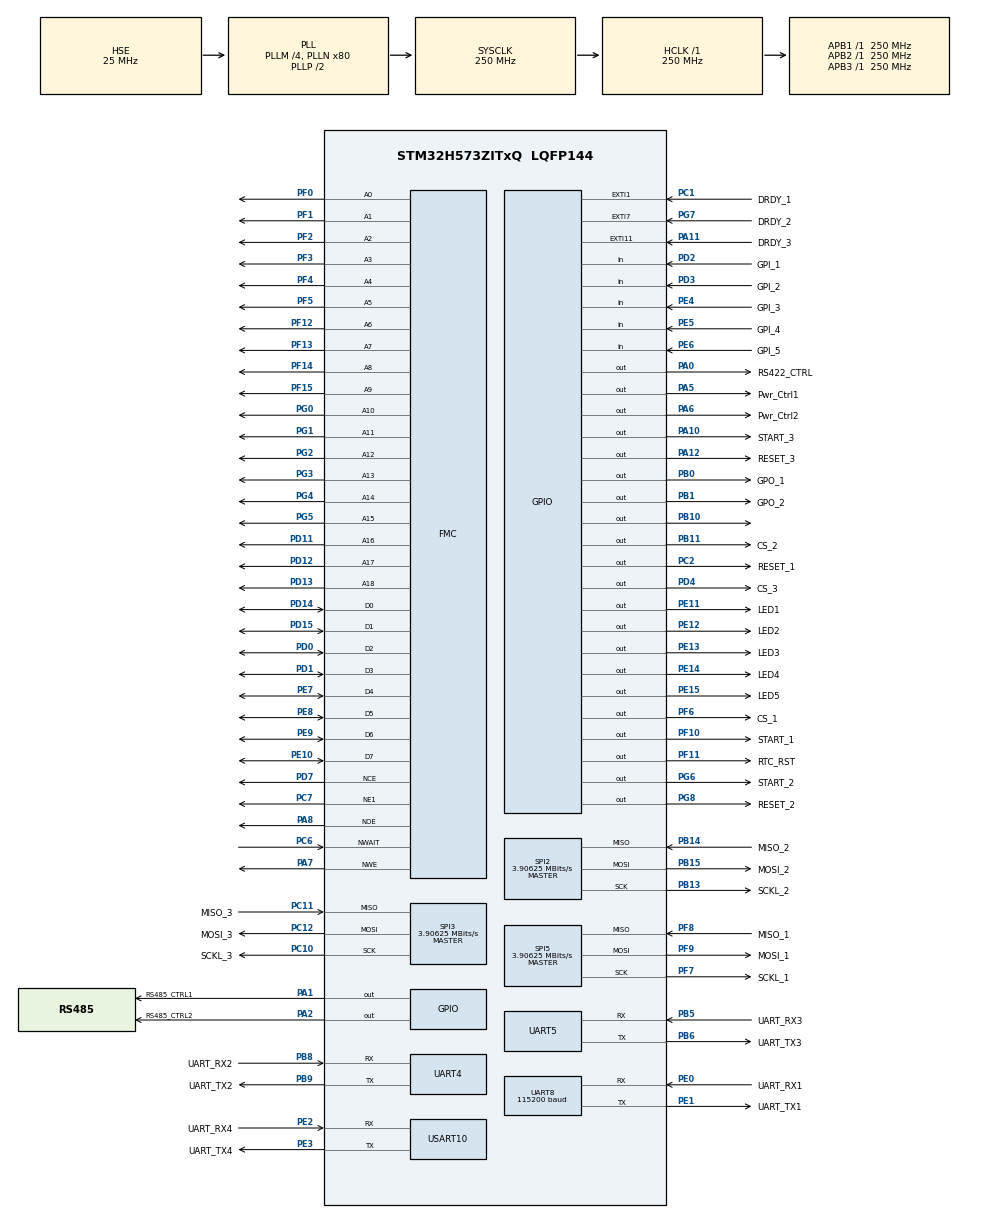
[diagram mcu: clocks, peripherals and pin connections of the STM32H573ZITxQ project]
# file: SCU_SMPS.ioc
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BOOTPATH.BootPathName=LEGACY
BOOTPATH.UserSelectedBootPath=LEGACY
CORTEX_M33_NS.userName=CORTEX_M33
FMC.AttributeSpaceHiZSetupTime1=9
FMC.AttributeSpaceHoldSetupTime1=10
FMC.AttributeSpaceSetupTime1=19
FMC.AttributeSpaceWaitSetupTime1=19
FMC.CommonSpaceHiZSetupTime1=3
FMC.CommonSpaceHoldSetupTime1=6
FMC.CommonSpaceSetupTime1=19
FMC.CommonSpaceWaitSetupTime1=19
FMC.DataHoldTime1=3
FMC.ECCPageSize1=FMC_NAND_ECC_PAGE_SIZE_8192BYTE
FMC.EccComputation1=FMC_NAND_ECC_ENABLE
FMC.NandBlockNbr1=4096
FMC.NandBlockSize1=128
FMC.NandExtraCommandEnable1=DISABLE
FMC.NandPageSize1=8192
FMC.NandPlaneNbr1=2
FMC.NandPlaneSize1=2048
FMC.NandSpareAreaSize1=448
FMC.TARSetupTime1=15
FMC.TCLRSetupTime1=15
FMC.WriteOperation1=FMC_WRITE_OPERATION_ENABLE
Mcu.Family=STM32H5
Mcu.Name=STM32H573ZITxQ
Mcu.Package=LQFP144
NVIC.EXTI11_IRQn=true\:0\:0\:false\:false\:true\:true\:true\:true
NVIC.EXTI1_IRQn=true\:0\:0\:false\:false\:true\:true\:true\:true
NVIC.EXTI7_IRQn=true\:0\:0\:false\:false\:true\:true\:true\:true
NVIC.PriorityGroup=NVIC_PRIORITYGROUP_4
NVIC.UART4_IRQn=true\:0\:0\:false\:false\:true\:true\:true\:true
NVIC.UART5_IRQn=true\:0\:0\:false\:false\:true\:true\:true\:true
NVIC.UART8_IRQn=true\:0\:0\:false\:false\:true\:true\:true\:true
PA0.GPIO_Label=RS422_CTRL
PA0.PinAttribute=Free
PA0.Signal=GPIO_Output
PA1.GPIO_Label=RS485_CTRL1
PA1.PinAttribute=Free
PA1.Signal=GPIO_Output
PA10.GPIO_Label=START_3
PA10.GPIO_Speed=GPIO_SPEED_FREQ_VERY_HIGH
PA10.Signal=GPIO_Output
PA11.GPIO_Label=DRDY_3
PA11.GPIO_ModeDefaultEXTI=GPIO_MODE_IT_FALLING
PA11.Signal=GPXTI11
PA12.GPIO_Label=RESET_3
PA12.GPIO_Speed=GPIO_SPEED_FREQ_VERY_HIGH
PA12.Signal=GPIO_Output
PA2.GPIO_Label=RS485_CTRL2
PA2.PinAttribute=Free
PA2.Signal=GPIO_Output
PA5.GPIO_Label=Pwr_Ctrl1
PA5.PinAttribute=Free
PA5.Signal=GPIO_Output
PA6.GPIO_Label=Pwr_Ctrl2
PA6.PinAttribute=Free
PA6.Signal=GPIO_Output
PA7.PinAttribute=Free
PA7.Signal=FMC_NWE
PA8.Signal=FMC_NOE
PB0.GPIO_Label=GPO_1
PB0.PinAttribute=Free
PB0.Signal=GPIO_Output
PB1.GPIO_Label=GPO_2
PB1.PinAttribute=Free
PB1.Signal=GPIO_Output
PB10.GPIO_Speed=GPIO_SPEED_FREQ_VERY_HIGH
PB10.PinAttribute=Free
PB10.PinState=GPIO_PIN_SET
PB10.Signal=GPIO_Output
PB11.GPIO_Label=CS_2
PB11.GPIO_Speed=GPIO_SPEED_FREQ_VERY_HIGH
PB11.PinAttribute=Free
PB11.Signal=GPIO_Output
PB13.GPIO_Label=SCKL_2
PB13.Mode=Full_Duplex_Master
PB13.Signal=SPI2_SCK
PB14.GPIO_Label=MISO_2
PB14.Mode=Full_Duplex_Master
PB14.PinAttribute=Free
PB14.Signal=SPI2_MISO
PB15.GPIO_Label=MOSI_2
PB15.Mode=Full_Duplex_Master
PB15.PinAttribute=Free
PB15.Signal=SPI2_MOSI
PB5.GPIO_Label=UART_RX3
PB5.Mode=Asynchronous
PB5.PinAttribute=Free
PB5.Signal=UART5_RX
PB6.GPIO_Label=UART_TX3
PB6.Mode=Asynchronous
PB6.PinAttribute=Free
PB6.Signal=UART5_TX
PB8.GPIO_Label=UART_RX2
PB8.Mode=Asynchronous
PB8.PinAttribute=Free
PB8.Signal=UART4_RX
PB9.GPIO_Label=UART_TX2
PB9.Mode=Asynchronous
PB9.PinAttribute=Free
PB9.Signal=UART4_TX
PC1.GPIO_Label=DRDY_1
PC1.GPIO_ModeDefaultEXTI=GPIO_MODE_IT_FALLING
PC1.PinAttribute=Free
PC1.Signal=GPXTI1
PC10.GPIO_Label=SCKL_3
PC10.Mode=Full_Duplex_Master
PC10.Signal=SPI3_SCK
PC11.GPIO_Label=MISO_3
PC11.Mode=Full_Duplex_Master
PC11.Signal=SPI3_MISO
PC12.GPIO_Label=MOSI_3
PC12.Mode=Full_Duplex_Master
PC12.Signal=SPI3_MOSI
PC14-OSC32_IN(OSC32_IN).Mode=LSE-External-Oscillator
PC14-OSC32_IN(OSC32_IN).Signal=RCC_OSC32_IN
PC15-OSC32_OUT(OSC32_OUT).Mode=LSE-External-Oscillator
PC15-OSC32_OUT(OSC32_OUT).Signal=RCC_OSC32_OUT
PC2.GPIO_Label=RESET_1
PC2.GPIO_Speed=GPIO_SPEED_FREQ_VERY_HIGH
PC2.PinAttribute=Free
PC2.Signal=GPIO_Output
PC6.Signal=FMC_NWAIT
PC7.Mode=NorPsramChipSelect1_1
PC7.Signal=FMC_NE1
PD0.PinAttribute=Free
PD0.Signal=FMC_D2_DA2
PD1.PinAttribute=Free
PD1.Signal=FMC_D3_DA3
PD11.PinAttribute=Free
PD11.Signal=FMC_A16_CLE
PD12.PinAttribute=Free
PD12.Signal=FMC_A17_ALE
PD13.PinAttribute=Free
PD13.Signal=FMC_A18
PD14.PinAttribute=Free
PD14.Signal=FMC_D0_DA0
PD15.PinAttribute=Free
PD15.Signal=FMC_D1_DA1
PD2.GPIO_Label=GPI_1
PD2.PinAttribute=Free
PD2.Signal=GPIO_Input
PD3.GPIO_Label=GPI_2
PD3.PinAttribute=Free
PD3.Signal=GPIO_Input
PD4.GPIO_Label=CS_3
PD4.GPIO_Speed=GPIO_SPEED_FREQ_VERY_HIGH
PD4.PinAttribute=Free
PD4.Signal=GPIO_Output
PD7.Mode=NandChipSelect3_1
PD7.PinAttribute=Free
PD7.Signal=FMC_NCE
PE0.GPIO_Label=UART_RX1
PE0.Mode=Asynchronous
PE0.PinAttribute=Free
PE0.Signal=UART8_RX
PE1.GPIO_Label=UART_TX1
PE1.Mode=Asynchronous
PE1.PinAttribute=Free
PE1.Signal=UART8_TX
PE10.PinAttribute=Free
PE10.Signal=FMC_D7_DA7
PE11.GPIO_Label=LED1
PE11.PinAttribute=Free
PE11.Signal=GPIO_Output
PE12.GPIO_Label=LED2
PE12.PinAttribute=Free
PE12.Signal=GPIO_Output
PE13.GPIO_Label=LED3
PE13.PinAttribute=Free
PE13.Signal=GPIO_Output
PE14.GPIO_Label=LED4
PE14.PinAttribute=Free
PE14.Signal=GPIO_Output
PE15.GPIO_Label=LED5
PE15.PinAttribute=Free
PE15.Signal=GPIO_Output
PE2.GPIO_Label=UART_RX4
PE2.Mode=Asynchronous
PE2.PinAttribute=Free
PE2.Signal=USART10_RX
PE3.GPIO_Label=UART_TX4
PE3.Mode=Asynchronous
PE3.PinAttribute=Free
PE3.Signal=USART10_TX
PE4.GPIO_Label=GPI_3
PE4.PinAttribute=Free
PE4.Signal=GPIO_Input
PE5.GPIO_Label=GPI_4
PE5.Signal=GPIO_Input
PE6.GPIO_Label=GPI_5
PE6.Signal=GPIO_Input
PE7.Signal=FMC_D4_DA4
PE8.PinAttribute=Free
PE8.Signal=FMC_D5_DA5
PE9.PinAttribute=Free
PE9.Signal=FMC_D6_DA6
PF0.Signal=FMC_A0
PF1.Signal=FMC_A1
PF10.GPIO_Label=START_1 
PF10.GPIO_Speed=GPIO_SPEED_FREQ_VERY_HIGH
PF10.PinAttribute=Free
PF10.Signal=GPIO_Output
PF11.GPIO_Label=RTC_RST
PF11.PinAttribute=Free
PF11.Signal=GPIO_Output
PF12.PinAttribute=Free
PF12.Signal=FMC_A6
PF13.PinAttribute=Free
PF13.Signal=FMC_A7
PF14.PinAttribute=Free
PF14.Signal=FMC_A8
PF15.PinAttribute=Free
PF15.Signal=FMC_A9
PF2.Signal=FMC_A2
PF3.Signal=FMC_A3
PF4.Signal=FMC_A4
PF5.Signal=FMC_A5
PF6.GPIO_Label=CS_1
PF6.GPIO_Speed=GPIO_SPEED_FREQ_VERY_HIGH
PF6.Signal=GPIO_Output
PF7.GPIO_Label=SCKL_1
PF7.Mode=Full_Duplex_Master
PF7.Signal=SPI5_SCK
PF8.GPIO_Label=MISO_1
PF8.Mode=Full_Duplex_Master
PF8.PinAttribute=Free
PF8.Signal=SPI5_MISO
PF9.GPIO_Label=MOSI_1
PF9.Mode=Full_Duplex_Master
PF9.PinAttribute=Free
PF9.Signal=SPI5_MOSI
PG0.Signal=FMC_A10
PG1.Signal=FMC_A11
PG2.PinAttribute=Free
PG2.Signal=FMC_A12
PG3.Signal=FMC_A13
PG4.Signal=FMC_A14_BA0
PG5.Signal=FMC_A15_BA1
PG6.GPIO_Label=START_2 
PG6.GPIO_Speed=GPIO_SPEED_FREQ_VERY_HIGH
PG6.Signal=GPIO_Output
PG7.GPIO_Label=DRDY_2
PG7.GPIO_ModeDefaultEXTI=GPIO_MODE_IT_FALLING
PG7.Signal=GPXTI7
PG8.GPIO_Label=RESET_2
PG8.GPIO_Speed=GPIO_SPEED_FREQ_VERY_HIGH
PG8.Signal=GPIO_Output
PH0-OSC_IN(PH0).Mode=HSE-External-Oscillator
PH0-OSC_IN(PH0).Signal=RCC_OSC_IN
PH1-OSC_OUT(PH1).Mode=HSE-External-Oscillator
PH1-OSC_OUT(PH1).Signal=RCC_OSC_OUT
ProjectManager.HeapSize=0x200
ProjectManager.StackSize=0x400
ProjectManager.TargetToolchain=STM32CubeIDE
RCC.ADCFreq_Value=250000000
RCC.AHBFreq_Value=250000000
RCC.APB1Freq_Value=250000000
RCC.APB1TimFreq_Value=250000000
RCC.APB2Freq_Value=250000000
RCC.APB2TimFreq_Value=250000000
RCC.APB3Freq_Value=250000000
RCC.CSI_VALUE=4000000
RCC.CortexFreq_Value=250000000
RCC.EPOD_VALUE=25000000
RCC.HCLKFreq_Value=250000000
RCC.HSE_VALUE=25000000
RCC.HSI48_VALUE=48000000
RCC.HSI_VALUE=64000000
RCC.LSIRC_VALUE=32000
RCC.PLLM=4
RCC.PLLN=80
RCC.PLLSourceVirtual=RCC_PLL1_SOURCE_HSE
RCC.SYSCLKFreq_VALUE=250000000
RCC.SYSCLKSource=RCC_SYSCLKSOURCE_PLLCLK
RCC.USBFreq_Value=48000000
RCC.VCOOutputFreq_Value=500000000
SH.FMC_A0.0=FMC_A0,19b-a1
SH.FMC_A1.0=FMC_A1,19b-a1
SH.FMC_A10.0=FMC_A10,19b-a1
SH.FMC_A11.0=FMC_A11,19b-a1
SH.FMC_A12.0=FMC_A12,19b-a1
SH.FMC_A13.0=FMC_A13,19b-a1
SH.FMC_A14_BA0.0=FMC_A14,19b-a1
SH.FMC_A15_BA1.0=FMC_A15,19b-a1
SH.FMC_A16_CLE.0=FMC_A16,19b-a1
SH.FMC_A16_CLE.1=FMC_CLE,8b-dmux1
SH.FMC_A17_ALE.0=FMC_A17,19b-a1
SH.FMC_A17_ALE.1=FMC_ALE,8b-dmux1
SH.FMC_A18.0=FMC_A18,19b-a1
SH.FMC_A2.0=FMC_A2,19b-a1
SH.FMC_A3.0=FMC_A3,19b-a1
SH.FMC_A4.0=FMC_A4,19b-a1
SH.FMC_A5.0=FMC_A5,19b-a1
SH.FMC_A6.0=FMC_A6,19b-a1
SH.FMC_A7.0=FMC_A7,19b-a1
SH.FMC_A8.0=FMC_A8,19b-a1
SH.FMC_A9.0=FMC_A9,19b-a1
SH.FMC_D0_DA0.0=FMC_D0,8b-d1
SH.FMC_D0_DA0.1=FMC_D0,8b-dmux1
SH.FMC_D1_DA1.0=FMC_D1,8b-d1
SH.FMC_D1_DA1.1=FMC_D1,8b-dmux1
SH.FMC_D2_DA2.0=FMC_D2,8b-d1
SH.FMC_D2_DA2.1=FMC_D2,8b-dmux1
SH.FMC_D3_DA3.0=FMC_D3,8b-d1
SH.FMC_D3_DA3.1=FMC_D3,8b-dmux1
SH.FMC_D4_DA4.0=FMC_D4,8b-d1
SH.FMC_D4_DA4.1=FMC_D4,8b-dmux1
SH.FMC_D5_DA5.0=FMC_D5,8b-d1
SH.FMC_D5_DA5.1=FMC_D5,8b-dmux1
SH.FMC_D6_DA6.0=FMC_D6,8b-d1
SH.FMC_D6_DA6.1=FMC_D6,8b-dmux1
SH.FMC_D7_DA7.0=FMC_D7,8b-d1
SH.FMC_D7_DA7.1=FMC_D7,8b-dmux1
SH.FMC_NOE.0=FMC_NOE,Sram1
SH.FMC_NOE.1=FMC_NOE,8b-dmux1
SH.FMC_NWAIT.0=FMC_NWAIT,Wait1
SH.FMC_NWE.0=FMC_NWE,Sram1
SH.FMC_NWE.1=FMC_NWE,8b-dmux1
SPI2.BaudRatePrescaler=SPI_BAUDRATEPRESCALER_64
SPI2.CLKPhase=SPI_PHASE_2EDGE
SPI2.CalculateBaudRate=3.90625 MBits/s
SPI2.DataSize=SPI_DATASIZE_8BIT
SPI2.Direction=SPI_DIRECTION_2LINES
SPI2.Mode=SPI_MODE_MASTER
SPI2.VirtualType=VM_MASTER
SPI3.BaudRatePrescaler=SPI_BAUDRATEPRESCALER_64
SPI3.CLKPhase=SPI_PHASE_2EDGE
SPI3.CalculateBaudRate=3.90625 MBits/s
SPI3.DataSize=SPI_DATASIZE_8BIT
SPI3.Direction=SPI_DIRECTION_2LINES
SPI3.Mode=SPI_MODE_MASTER
SPI3.VirtualNSS=VM_NSSHARD
SPI3.VirtualType=VM_MASTER
SPI5.BaudRatePrescaler=SPI_BAUDRATEPRESCALER_64
SPI5.CLKPhase=SPI_PHASE_2EDGE
SPI5.CalculateBaudRate=3.90625 MBits/s
SPI5.DataSize=SPI_DATASIZE_8BIT
SPI5.Direction=SPI_DIRECTION_2LINES
SPI5.Mode=SPI_MODE_MASTER
SPI5.VirtualType=VM_MASTER
UART8.BaudRate=115200
UART8.TXFIFOThreshold=TXFIFO_THRESHOLD_EMPTY
USART10.VirtualMode=VM_ASYNC
USART10.VirtualMode-Asynchronous=VM_ASYNC
VP_BOOTPATH_VS_BOOTPATH.Mode=BP_Activate
VP_CORTEX_M33_NS_VS_Hclk.Mode=Hclk_Mode
VP_MEMORYMAP_VS_MEMORYMAP.Mode=CurAppReg
VP_PWR_VS_DBSignals.Mode=DisableDeadBatterySignals
VP_PWR_VS_LPOM.Mode=PowerOptimisation
VP_PWR_VS_SECSignals.Mode=Security/Privilege
board=custom

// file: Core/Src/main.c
/* USER CODE BEGIN Header */
/**
 ******************************************************************************
 * @file           : main.c
 * @brief          : Main program body
 ******************************************************************************
 * @attention
 *
 * Copyright (c) 2024 STMicroelectronics.
 * All rights reserved.
 *
 * This software is licensed under terms that can be found in the LICENSE file
 * in the root directory of this software component.
 * If no LICENSE file comes with this software, it is provided AS-IS.
 *
 ******************************************************************************
 */
/* USER CODE END Header */
#include "main.h"

/* USER CODE BEGIN Includes */
#include <stdio.h>
#include <string.h>
/* USER CODE END Includes */

SPI_HandleTypeDef hspi2;
SPI_HandleTypeDef hspi3;
SPI_HandleTypeDef hspi5;

UART_HandleTypeDef huart4;
UART_HandleTypeDef huart5;
UART_HandleTypeDef huart8;
UART_HandleTypeDef huart10;

SRAM_HandleTypeDef hsram1;
NAND_HandleTypeDef hnand1;

/* USER CODE BEGIN PV */

//const uint8_t WREG = 0x40; //00000011;
//const uint8_t RREG = 0x20; //00000011;
//const uint8_t RDATA = 0x12; //00000011;

extern uint8_t time_str[25];
uint32_t sramAddr ;
extern uint8_t pSrcBuffer ;
uint8_t read_flag = 0;
/* USER CODE END PV */

void SystemClock_Config(void);
static void MX_GPIO_Init(void);
static void MX_FMC_Init(void);
static void MX_SPI2_Init(void);
static void MX_SPI3_Init(void);
static void MX_SPI5_Init(void);
static void MX_UART4_Init(void);
static void MX_UART5_Init(void);
static void MX_UART8_Init(void);
static void MX_USART10_UART_Init(void);
/* USER CODE BEGIN PFP */
float ADC_READ(uint8_t adc_num,uint8_t channel);
void UART_InitAllHandlers(void) ;
/* USER CODE END PFP */

/* USER CODE BEGIN 0 */

#define BufferSize 1

extern uint8_t buffer2[25];

uint8_t time_str[25]={0};
uint8_t time_str_length = 0 ;

extern uint8_t command_str[15];
extern uint8_t command_str_index;
uint8_t command_rcv ;
extern uint8_t ATP_test ;

uint8_t uart1_rx_buffer[1];
uint8_t uart2_rx_buffer[1];
uint8_t uart5_rx_buffer;
uint8_t rcv;
uint8_t time_rcv=0;
uint8_t time_set = 0;
uint8_t uart3_rx_buffer[1];
uint8_t uart4_rx_buffer[1];
extern NAND_AddressTypeDef nand_address;
/*
 * variables declaration for NAND Flash
 */
uint8_t NAND_Buf[15]={0};
uint8_t NAND_index = 0;
uint8_t NAND_flag=0;

/* USER CODE END 0 */

int main(void)
{

  /* MCU Configuration--------------------------------------------------------*/

  /* Reset of all peripherals, Initializes the Flash interface and the Systick. */
  HAL_Init();

  /* Configure the system clock */
  SystemClock_Config();

  /* Initialize all configured peripherals */
  MX_GPIO_Init();
  MX_FMC_Init();
  MX_SPI2_Init();
  MX_SPI3_Init();
  MX_SPI5_Init();
  MX_UART4_Init();
  MX_UART5_Init();
  MX_UART8_Init();
  MX_USART10_UART_Init();
  /* USER CODE BEGIN 2 */
	UART_InitAllHandlers();
  /* USER CODE END 2 */

  /* Infinite loop */
  /* USER CODE BEGIN WHILE */
	sramAddr = 0x60000000 | 0x7FFF8;
	pSrcBuffer = 0x00;
	HAL_SRAM_Write_8b(&hsram1,(uint32_t *)sramAddr,&pSrcBuffer,BufferSize);
	HAL_NAND_Reset(&hnand1);

	HAL_GPIO_WritePin(GPIOC, RESET_1_Pin, 1);
	HAL_Delay(1);
	HAL_GPIO_WritePin(GPIOC, RESET_1_Pin, 0);
	HAL_Delay(1);
	HAL_GPIO_WritePin(GPIOC, RESET_1_Pin, 1);
	HAL_Delay(1);

	HAL_GPIO_WritePin(GPIOG, RESET_2_Pin, 1);
	HAL_Delay(1);
	HAL_GPIO_WritePin(GPIOG, RESET_2_Pin, 0);
	HAL_Delay(1);
	HAL_GPIO_WritePin(GPIOG, RESET_2_Pin, 1);
	HAL_Delay(1);

	HAL_GPIO_WritePin(GPIOA, RESET_3_Pin, 1);
	HAL_Delay(1);
	HAL_GPIO_WritePin(GPIOA, RESET_3_Pin, 0);
	HAL_Delay(1);
	HAL_GPIO_WritePin(GPIOA, RESET_3_Pin, 1);
	HAL_Delay(10);
	//set_NAND_block_status();
	get_NAND_block_status();
	get_NAND_address();
	HAL_GPIO_WritePin(GPIOA, RS485_CTRL2_Pin, GPIO_PIN_RESET);
	char buffe33r[] = "HELLO";
	//nand_address.Block=0;
	while (1)
	{
#if 0
		HAL_NAND_Erase_Block(&hnand1, &nand_address);
		nand_address.Block++;
		if(nand_address.Block = 200)
		{
			nand_address.Page=0;
			nand_address.Block=0;
			nand_address.Plane=0;
			update_NAND_addr();
			while (1);
		}
#endif

		ADC_operation();
		NAND_operation();
		SRAM_operation();
		//		if(1)
		//		{
		//
		//			HAL_GPIO_WritePin(GPIOA, RS485_CTRL2_Pin, GPIO_PIN_SET);
		//			HAL_Delay(100);
		//			HAL_UART_Transmit_IT(&huart4, (uint8_t *)buffe33r, strlen(buffe33r));
		//			HAL_Delay(100);
		//			HAL_GPIO_WritePin(GPIOA, RS485_CTRL2_Pin, GPIO_PIN_RESET);
		//			HAL_Delay(100);
		//			time_set = 0 ;
		//
		//		}

		//		while( 1 || ( HAL_GPIO_ReadPin(GPIOE,GPI_3_Pin)  && HAL_GPIO_ReadPin (GPIOD,GPI_2_Pin)))
		//		{
		//			// ATP MODE ENTRY
		//
//							ATP_operation();
		//
		//			if(time_set)
		//			{
		//				time_set = 0 ;
		//				time_setter();
		//
		//			}
		//		}

    /* USER CODE END WHILE */

	}
}

void SystemClock_Config(void)
{
  RCC_OscInitTypeDef RCC_OscInitStruct = {0};
  RCC_ClkInitTypeDef RCC_ClkInitStruct = {0};

  /** Configure the main internal regulator output voltage
  */
  __HAL_PWR_VOLTAGESCALING_CONFIG(PWR_REGULATOR_VOLTAGE_SCALE0);

  while(!__HAL_PWR_GET_FLAG(PWR_FLAG_VOSRDY)) {}

  /** Initializes the RCC Oscillators according to the specified parameters
  * in the RCC_OscInitTypeDef structure.
  */
  RCC_OscInitStruct.OscillatorType = RCC_OSCILLATORTYPE_HSE;
  RCC_OscInitStruct.HSEState = RCC_HSE_ON;
  RCC_OscInitStruct.PLL.PLLState = RCC_PLL_ON;
  RCC_OscInitStruct.PLL.PLLSource = RCC_PLL1_SOURCE_HSE;
  RCC_OscInitStruct.PLL.PLLM = 4;
  RCC_OscInitStruct.PLL.PLLN = 80;
  RCC_OscInitStruct.PLL.PLLP = 2;
  RCC_OscInitStruct.PLL.PLLQ = 2;
  RCC_OscInitStruct.PLL.PLLR = 2;
  RCC_OscInitStruct.PLL.PLLRGE = RCC_PLL1_VCIRANGE_2;
  RCC_OscInitStruct.PLL.PLLVCOSEL = RCC_PLL1_VCORANGE_WIDE;
  RCC_OscInitStruct.PLL.PLLFRACN = 0;
  if (HAL_RCC_OscConfig(&RCC_OscInitStruct) != HAL_OK)
  {
    Error_Handler();
  }

  /** Initializes the CPU, AHB and APB buses clocks
  */
  RCC_ClkInitStruct.ClockType = RCC_CLOCKTYPE_HCLK|RCC_CLOCKTYPE_SYSCLK
                              |RCC_CLOCKTYPE_PCLK1|RCC_CLOCKTYPE_PCLK2
                              |RCC_CLOCKTYPE_PCLK3;
  RCC_ClkInitStruct.SYSCLKSource = RCC_SYSCLKSOURCE_PLLCLK;
  RCC_ClkInitStruct.AHBCLKDivider = RCC_SYSCLK_DIV1;
  RCC_ClkInitStruct.APB1CLKDivider = RCC_HCLK_DIV1;
  RCC_ClkInitStruct.APB2CLKDivider = RCC_HCLK_DIV1;
  RCC_ClkInitStruct.APB3CLKDivider = RCC_HCLK_DIV1;

  if (HAL_RCC_ClockConfig(&RCC_ClkInitStruct, FLASH_LATENCY_5) != HAL_OK)
  {
    Error_Handler();
  }

  /** Configure the programming delay
  */
  __HAL_FLASH_SET_PROGRAM_DELAY(FLASH_PROGRAMMING_DELAY_2);
}

static void MX_SPI2_Init(void)
{

  /* SPI2 parameter configuration*/
  hspi2.Instance = SPI2;
  hspi2.Init.Mode = SPI_MODE_MASTER;
  hspi2.Init.Direction = SPI_DIRECTION_2LINES;
  hspi2.Init.DataSize = SPI_DATASIZE_8BIT;
  hspi2.Init.CLKPolarity = SPI_POLARITY_LOW;
  hspi2.Init.CLKPhase = SPI_PHASE_2EDGE;
  hspi2.Init.NSS = SPI_NSS_SOFT;
  hspi2.Init.BaudRatePrescaler = SPI_BAUDRATEPRESCALER_64;
  hspi2.Init.FirstBit = SPI_FIRSTBIT_MSB;
  hspi2.Init.TIMode = SPI_TIMODE_DISABLE;
  hspi2.Init.CRCCalculation = SPI_CRCCALCULATION_DISABLE;
  hspi2.Init.CRCPolynomial = 0x7;
  hspi2.Init.NSSPMode = SPI_NSS_PULSE_DISABLE;
  hspi2.Init.NSSPolarity = SPI_NSS_POLARITY_LOW;
  hspi2.Init.FifoThreshold = SPI_FIFO_THRESHOLD_01DATA;
  hspi2.Init.MasterSSIdleness = SPI_MASTER_SS_IDLENESS_00CYCLE;
  hspi2.Init.MasterInterDataIdleness = SPI_MASTER_INTERDATA_IDLENESS_00CYCLE;
  hspi2.Init.MasterReceiverAutoSusp = SPI_MASTER_RX_AUTOSUSP_DISABLE;
  hspi2.Init.MasterKeepIOState = SPI_MASTER_KEEP_IO_STATE_DISABLE;
  hspi2.Init.IOSwap = SPI_IO_SWAP_DISABLE;
  hspi2.Init.ReadyMasterManagement = SPI_RDY_MASTER_MANAGEMENT_INTERNALLY;
  hspi2.Init.ReadyPolarity = SPI_RDY_POLARITY_HIGH;
  if (HAL_SPI_Init(&hspi2) != HAL_OK)
  {
    Error_Handler();
  }

}

static void MX_SPI3_Init(void)
{

  /* SPI3 parameter configuration*/
  hspi3.Instance = SPI3;
  hspi3.Init.Mode = SPI_MODE_MASTER;
  hspi3.Init.Direction = SPI_DIRECTION_2LINES;
  hspi3.Init.DataSize = SPI_DATASIZE_8BIT;
  hspi3.Init.CLKPolarity = SPI_POLARITY_LOW;
  hspi3.Init.CLKPhase = SPI_PHASE_2EDGE;
  hspi3.Init.NSS = SPI_NSS_SOFT;
  hspi3.Init.BaudRatePrescaler = SPI_BAUDRATEPRESCALER_64;
  hspi3.Init.FirstBit = SPI_FIRSTBIT_MSB;
  hspi3.Init.TIMode = SPI_TIMODE_DISABLE;
  hspi3.Init.CRCCalculation = SPI_CRCCALCULATION_DISABLE;
  hspi3.Init.CRCPolynomial = 0x7;
  hspi3.Init.NSSPMode = SPI_NSS_PULSE_DISABLE;
  hspi3.Init.NSSPolarity = SPI_NSS_POLARITY_LOW;
  hspi3.Init.FifoThreshold = SPI_FIFO_THRESHOLD_01DATA;
  hspi3.Init.MasterSSIdleness = SPI_MASTER_SS_IDLENESS_00CYCLE;
  hspi3.Init.MasterInterDataIdleness = SPI_MASTER_INTERDATA_IDLENESS_00CYCLE;
  hspi3.Init.MasterReceiverAutoSusp = SPI_MASTER_RX_AUTOSUSP_DISABLE;
  hspi3.Init.MasterKeepIOState = SPI_MASTER_KEEP_IO_STATE_DISABLE;
  hspi3.Init.IOSwap = SPI_IO_SWAP_DISABLE;
  hspi3.Init.ReadyMasterManagement = SPI_RDY_MASTER_MANAGEMENT_INTERNALLY;
  hspi3.Init.ReadyPolarity = SPI_RDY_POLARITY_HIGH;
  if (HAL_SPI_Init(&hspi3) != HAL_OK)
  {
    Error_Handler();
  }

}

static void MX_SPI5_Init(void)
{

  /* SPI5 parameter configuration*/
  hspi5.Instance = SPI5;
  hspi5.Init.Mode = SPI_MODE_MASTER;
  hspi5.Init.Direction = SPI_DIRECTION_2LINES;
  hspi5.Init.DataSize = SPI_DATASIZE_8BIT;
  hspi5.Init.CLKPolarity = SPI_POLARITY_LOW;
  hspi5.Init.CLKPhase = SPI_PHASE_2EDGE;
  hspi5.Init.NSS = SPI_NSS_SOFT;
  hspi5.Init.BaudRatePrescaler = SPI_BAUDRATEPRESCALER_64;
  hspi5.Init.FirstBit = SPI_FIRSTBIT_MSB;
  hspi5.Init.TIMode = SPI_TIMODE_DISABLE;
  hspi5.Init.CRCCalculation = SPI_CRCCALCULATION_DISABLE;
  hspi5.Init.CRCPolynomial = 0x7;
  hspi5.Init.NSSPMode = SPI_NSS_PULSE_DISABLE;
  hspi5.Init.NSSPolarity = SPI_NSS_POLARITY_LOW;
  hspi5.Init.FifoThreshold = SPI_FIFO_THRESHOLD_01DATA;
  hspi5.Init.MasterSSIdleness = SPI_MASTER_SS_IDLENESS_00CYCLE;
  hspi5.Init.MasterInterDataIdleness = SPI_MASTER_INTERDATA_IDLENESS_00CYCLE;
  hspi5.Init.MasterReceiverAutoSusp = SPI_MASTER_RX_AUTOSUSP_DISABLE;
  hspi5.Init.MasterKeepIOState = SPI_MASTER_KEEP_IO_STATE_DISABLE;
  hspi5.Init.IOSwap = SPI_IO_SWAP_DISABLE;
  hspi5.Init.ReadyMasterManagement = SPI_RDY_MASTER_MANAGEMENT_INTERNALLY;
  hspi5.Init.ReadyPolarity = SPI_RDY_POLARITY_HIGH;
  if (HAL_SPI_Init(&hspi5) != HAL_OK)
  {
    Error_Handler();
  }

}

static void MX_UART4_Init(void)
{

  huart4.Instance = UART4;
  huart4.Init.BaudRate = 115200;
  huart4.Init.WordLength = UART_WORDLENGTH_8B;
  huart4.Init.StopBits = UART_STOPBITS_1;
  huart4.Init.Parity = UART_PARITY_NONE;
  huart4.Init.Mode = UART_MODE_TX_RX;
  huart4.Init.HwFlowCtl = UART_HWCONTROL_NONE;
  huart4.Init.OverSampling = UART_OVERSAMPLING_16;
  huart4.Init.OneBitSampling = UART_ONE_BIT_SAMPLE_DISABLE;
  huart4.Init.ClockPrescaler = UART_PRESCALER_DIV1;
  huart4.AdvancedInit.AdvFeatureInit = UART_ADVFEATURE_NO_INIT;
  if (HAL_UART_Init(&huart4) != HAL_OK)
  {
    Error_Handler();
  }
  if (HAL_UARTEx_SetTxFifoThreshold(&huart4, UART_TXFIFO_THRESHOLD_1_8) != HAL_OK)
  {
    Error_Handler();
  }
  if (HAL_UARTEx_SetRxFifoThreshold(&huart4, UART_RXFIFO_THRESHOLD_1_8) != HAL_OK)
  {
    Error_Handler();
  }
  if (HAL_UARTEx_DisableFifoMode(&huart4) != HAL_OK)
  {
    Error_Handler();
  }

}

static void MX_UART5_Init(void)
{

  huart5.Instance = UART5;
  huart5.Init.BaudRate = 115200;
  huart5.Init.WordLength = UART_WORDLENGTH_8B;
  huart5.Init.StopBits = UART_STOPBITS_1;
  huart5.Init.Parity = UART_PARITY_NONE;
  huart5.Init.Mode = UART_MODE_TX_RX;
  huart5.Init.HwFlowCtl = UART_HWCONTROL_NONE;
  huart5.Init.OverSampling = UART_OVERSAMPLING_16;
  huart5.Init.OneBitSampling = UART_ONE_BIT_SAMPLE_DISABLE;
  huart5.Init.ClockPrescaler = UART_PRESCALER_DIV1;
  huart5.AdvancedInit.AdvFeatureInit = UART_ADVFEATURE_NO_INIT;
  if (HAL_UART_Init(&huart5) != HAL_OK)
  {
    Error_Handler();
  }
  if (HAL_UARTEx_SetTxFifoThreshold(&huart5, UART_TXFIFO_THRESHOLD_1_8) != HAL_OK)
  {
    Error_Handler();
  }
  if (HAL_UARTEx_SetRxFifoThreshold(&huart5, UART_RXFIFO_THRESHOLD_1_8) != HAL_OK)
  {
    Error_Handler();
  }
  if (HAL_UARTEx_DisableFifoMode(&huart5) != HAL_OK)
  {
    Error_Handler();
  }

}

static void MX_UART8_Init(void)
{

  huart8.Instance = UART8;
  huart8.Init.BaudRate = 115200;
  huart8.Init.WordLength = UART_WORDLENGTH_8B;
  huart8.Init.StopBits = UART_STOPBITS_1;
  huart8.Init.Parity = UART_PARITY_NONE;
  huart8.Init.Mode = UART_MODE_TX_RX;
  huart8.Init.HwFlowCtl = UART_HWCONTROL_NONE;
  huart8.Init.OverSampling = UART_OVERSAMPLING_16;
  huart8.Init.OneBitSampling = UART_ONE_BIT_SAMPLE_DISABLE;
  huart8.Init.ClockPrescaler = UART_PRESCALER_DIV1;
  huart8.AdvancedInit.AdvFeatureInit = UART_ADVFEATURE_NO_INIT;
  if (HAL_UART_Init(&huart8) != HAL_OK)
  {
    Error_Handler();
  }
  if (HAL_UARTEx_SetTxFifoThreshold(&huart8, UART_TXFIFO_THRESHOLD_8_8) != HAL_OK)
  {
    Error_Handler();
  }
  if (HAL_UARTEx_SetRxFifoThreshold(&huart8, UART_RXFIFO_THRESHOLD_1_8) != HAL_OK)
  {
    Error_Handler();
  }
  if (HAL_UARTEx_DisableFifoMode(&huart8) != HAL_OK)
  {
    Error_Handler();
  }

}

static void MX_USART10_UART_Init(void)
{

  huart10.Instance = USART10;
  huart10.Init.BaudRate = 115200;
  huart10.Init.WordLength = UART_WORDLENGTH_8B;
  huart10.Init.StopBits = UART_STOPBITS_1;
  huart10.Init.Parity = UART_PARITY_NONE;
  huart10.Init.Mode = UART_MODE_TX_RX;
  huart10.Init.HwFlowCtl = UART_HWCONTROL_NONE;
  huart10.Init.OverSampling = UART_OVERSAMPLING_16;
  huart10.Init.OneBitSampling = UART_ONE_BIT_SAMPLE_DISABLE;
  huart10.Init.ClockPrescaler = UART_PRESCALER_DIV1;
  huart10.AdvancedInit.AdvFeatureInit = UART_ADVFEATURE_NO_INIT;
  if (HAL_UART_Init(&huart10) != HAL_OK)
  {
    Error_Handler();
  }
  if (HAL_UARTEx_SetTxFifoThreshold(&huart10, UART_TXFIFO_THRESHOLD_1_8) != HAL_OK)
  {
    Error_Handler();
  }
  if (HAL_UARTEx_SetRxFifoThreshold(&huart10, UART_RXFIFO_THRESHOLD_1_8) != HAL_OK)
  {
    Error_Handler();
  }
  if (HAL_UARTEx_DisableFifoMode(&huart10) != HAL_OK)
  {
    Error_Handler();
  }

}

/* FMC initialization function */
static void MX_FMC_Init(void)
{

  FMC_NORSRAM_TimingTypeDef Timing = {0};
  FMC_NAND_PCC_TimingTypeDef ComSpaceTiming = {0};
  FMC_NAND_PCC_TimingTypeDef AttSpaceTiming = {0};

  /** Perform the SRAM1 memory initialization sequence
  */
  hsram1.Instance = FMC_NORSRAM_DEVICE;
  hsram1.Extended = FMC_NORSRAM_EXTENDED_DEVICE;
  /* hsram1.Init */
  hsram1.Init.NSBank = FMC_NORSRAM_BANK1;
  hsram1.Init.DataAddressMux = FMC_DATA_ADDRESS_MUX_DISABLE;
  hsram1.Init.MemoryType = FMC_MEMORY_TYPE_SRAM;
  hsram1.Init.MemoryDataWidth = FMC_NORSRAM_MEM_BUS_WIDTH_8;
  hsram1.Init.BurstAccessMode = FMC_BURST_ACCESS_MODE_DISABLE;
  hsram1.Init.WaitSignalPolarity = FMC_WAIT_SIGNAL_POLARITY_LOW;
  hsram1.Init.WaitSignalActive = FMC_WAIT_TIMING_BEFORE_WS;
  hsram1.Init.WriteOperation = FMC_WRITE_OPERATION_ENABLE;
  hsram1.Init.WaitSignal = FMC_WAIT_SIGNAL_DISABLE;
  hsram1.Init.ExtendedMode = FMC_EXTENDED_MODE_DISABLE;
  hsram1.Init.AsynchronousWait = FMC_ASYNCHRONOUS_WAIT_DISABLE;
  hsram1.Init.WriteBurst = FMC_WRITE_BURST_DISABLE;
  hsram1.Init.ContinuousClock = FMC_CONTINUOUS_CLOCK_SYNC_ONLY;
  hsram1.Init.WriteFifo = FMC_WRITE_FIFO_ENABLE;
  hsram1.Init.NBLSetupTime = 0;
  hsram1.Init.PageSize = FMC_PAGE_SIZE_NONE;
  hsram1.Init.MaxChipSelectPulse = DISABLE;
  /* Timing */
  Timing.AddressSetupTime = 15;
  Timing.AddressHoldTime = 15;
  Timing.DataSetupTime = 255;
  Timing.DataHoldTime = 3;
  Timing.BusTurnAroundDuration = 15;
  Timing.CLKDivision = 16;
  Timing.DataLatency = 17;
  Timing.AccessMode = FMC_ACCESS_MODE_A;
  /* ExtTiming */

  if (HAL_SRAM_Init(&hsram1, &Timing, NULL) != HAL_OK)
  {
    Error_Handler( );
  }

  /** Perform the NAND1 memory initialization sequence
  */
  hnand1.Instance = FMC_NAND_DEVICE;
  /* hnand1.Init */
  hnand1.Init.NandBank = FMC_NAND_BANK3;
  hnand1.Init.Waitfeature = FMC_NAND_WAIT_FEATURE_ENABLE;
  hnand1.Init.MemoryDataWidth = FMC_NAND_MEM_BUS_WIDTH_8;
  hnand1.Init.EccComputation = FMC_NAND_ECC_ENABLE;
  hnand1.Init.ECCPageSize = FMC_NAND_ECC_PAGE_SIZE_8192BYTE;
  hnand1.Init.TCLRSetupTime = 15;
  hnand1.Init.TARSetupTime = 15;
  /* hnand1.Config */
  hnand1.Config.PageSize = 8192;
  hnand1.Config.SpareAreaSize = 448;
  hnand1.Config.BlockSize = 128;
  hnand1.Config.BlockNbr = 4096;
  hnand1.Config.PlaneNbr = 2;
  hnand1.Config.PlaneSize = 2048;
  hnand1.Config.ExtraCommandEnable = DISABLE;
  /* ComSpaceTiming */
  ComSpaceTiming.SetupTime = 19;
  ComSpaceTiming.WaitSetupTime = 19;
  ComSpaceTiming.HoldSetupTime = 6;
  ComSpaceTiming.HiZSetupTime = 3;
  /* AttSpaceTiming */
  AttSpaceTiming.SetupTime = 19;
  AttSpaceTiming.WaitSetupTime = 19;
  AttSpaceTiming.HoldSetupTime = 10;
  AttSpaceTiming.HiZSetupTime = 9;

  if (HAL_NAND_Init(&hnand1, &ComSpaceTiming, &AttSpaceTiming) != HAL_OK)
  {
    Error_Handler( );
  }

}

static void MX_GPIO_Init(void)
{
  GPIO_InitTypeDef GPIO_InitStruct = {0};

  /* GPIO Ports Clock Enable */
  __HAL_RCC_GPIOE_CLK_ENABLE();
  __HAL_RCC_GPIOC_CLK_ENABLE();
  __HAL_RCC_GPIOF_CLK_ENABLE();
  __HAL_RCC_GPIOH_CLK_ENABLE();
  __HAL_RCC_GPIOA_CLK_ENABLE();
  __HAL_RCC_GPIOB_CLK_ENABLE();
  __HAL_RCC_GPIOG_CLK_ENABLE();
  __HAL_RCC_GPIOD_CLK_ENABLE();

  /*Configure GPIO pin Output Level */
  HAL_GPIO_WritePin(GPIOF, CS_1_Pin|START_1_Pin|RTC_RST_Pin, GPIO_PIN_RESET);

  /*Configure GPIO pin Output Level */
  HAL_GPIO_WritePin(RESET_1_GPIO_Port, RESET_1_Pin, GPIO_PIN_RESET);

  /*Configure GPIO pin Output Level */
  HAL_GPIO_WritePin(GPIOA, RS422_CTRL_Pin|RS485_CTRL1_Pin|RS485_CTRL2_Pin|Pwr_Ctrl1_Pin
                          |Pwr_Ctrl2_Pin|START_3_Pin|RESET_3_Pin, GPIO_PIN_RESET);

  /*Configure GPIO pin Output Level */
  HAL_GPIO_WritePin(GPIOB, GPO_1_Pin|GPO_2_Pin|CS_2_Pin, GPIO_PIN_RESET);

  /*Configure GPIO pin Output Level */
  HAL_GPIO_WritePin(GPIOE, LED1_Pin|LED2_Pin|LED3_Pin|LED4_Pin
                          |LED5_Pin, GPIO_PIN_RESET);

  /*Configure GPIO pin Output Level */
  HAL_GPIO_WritePin(GPIOB, GPIO_PIN_10, GPIO_PIN_SET);

  /*Configure GPIO pin Output Level */
  HAL_GPIO_WritePin(GPIOG, START_2_Pin|RESET_2_Pin, GPIO_PIN_RESET);

  /*Configure GPIO pin Output Level */
  HAL_GPIO_WritePin(CS_3_GPIO_Port, CS_3_Pin, GPIO_PIN_RESET);

  /*Configure GPIO pins : GPI_3_Pin GPI_4_Pin GPI_5_Pin */
  GPIO_InitStruct.Pin = GPI_3_Pin|GPI_4_Pin|GPI_5_Pin;
  GPIO_InitStruct.Mode = GPIO_MODE_INPUT;
  GPIO_InitStruct.Pull = GPIO_NOPULL;
  HAL_GPIO_Init(GPIOE, &GPIO_InitStruct);

  /*Configure GPIO pins : CS_1_Pin START_1_Pin */
  GPIO_InitStruct.Pin = CS_1_Pin|START_1_Pin;
  GPIO_InitStruct.Mode = GPIO_MODE_OUTPUT_PP;
  GPIO_InitStruct.Pull = GPIO_NOPULL;
  GPIO_InitStruct.Speed = GPIO_SPEED_FREQ_VERY_HIGH;
  HAL_GPIO_Init(GPIOF, &GPIO_InitStruct);

  /*Configure GPIO pin : DRDY_1_Pin */
  GPIO_InitStruct.Pin = DRDY_1_Pin;
  GPIO_InitStruct.Mode = GPIO_MODE_IT_FALLING;
  GPIO_InitStruct.Pull = GPIO_NOPULL;
  HAL_GPIO_Init(DRDY_1_GPIO_Port, &GPIO_InitStruct);

  /*Configure GPIO pin : RESET_1_Pin */
  GPIO_InitStruct.Pin = RESET_1_Pin;
  GPIO_InitStruct.Mode = GPIO_MODE_OUTPUT_PP;
  GPIO_InitStruct.Pull = GPIO_NOPULL;
  GPIO_InitStruct.Speed = GPIO_SPEED_FREQ_VERY_HIGH;
  HAL_GPIO_Init(RESET_1_GPIO_Port, &GPIO_InitStruct);

  /*Configure GPIO pins : RS422_CTRL_Pin RS485_CTRL1_Pin RS485_CTRL2_Pin Pwr_Ctrl1_Pin
                           Pwr_Ctrl2_Pin */
  GPIO_InitStruct.Pin = RS422_CTRL_Pin|RS485_CTRL1_Pin|RS485_CTRL2_Pin|Pwr_Ctrl1_Pin
                          |Pwr_Ctrl2_Pin;
  GPIO_InitStruct.Mode = GPIO_MODE_OUTPUT_PP;
  GPIO_InitStruct.Pull = GPIO_NOPULL;
  GPIO_InitStruct.Speed = GPIO_SPEED_FREQ_LOW;
  HAL_GPIO_Init(GPIOA, &GPIO_InitStruct);

  /*Configure GPIO pins : GPO_1_Pin GPO_2_Pin */
  GPIO_InitStruct.Pin = GPO_1_Pin|GPO_2_Pin;
  GPIO_InitStruct.Mode = GPIO_MODE_OUTPUT_PP;
  GPIO_InitStruct.Pull = GPIO_NOPULL;
  GPIO_InitStruct.Speed = GPIO_SPEED_FREQ_LOW;
  HAL_GPIO_Init(GPIOB, &GPIO_InitStruct);

  /*Configure GPIO pin : RTC_RST_Pin */
  GPIO_InitStruct.Pin = RTC_RST_Pin;
  GPIO_InitStruct.Mode = GPIO_MODE_OUTPUT_PP;
  GPIO_InitStruct.Pull = GPIO_NOPULL;
  GPIO_InitStruct.Speed = GPIO_SPEED_FREQ_LOW;
  HAL_GPIO_Init(RTC_RST_GPIO_Port, &GPIO_InitStruct);

  /*Configure GPIO pins : LED1_Pin LED2_Pin LED3_Pin LED4_Pin
                           LED5_Pin */
  GPIO_InitStruct.Pin = LED1_Pin|LED2_Pin|LED3_Pin|LED4_Pin
                          |LED5_Pin;
  GPIO_InitStruct.Mode = GPIO_MODE_OUTPUT_PP;
  GPIO_InitStruct.Pull = GPIO_NOPULL;
  GPIO_InitStruct.Speed = GPIO_SPEED_FREQ_LOW;
  HAL_GPIO_Init(GPIOE, &GPIO_InitStruct);

  /*Configure GPIO pins : PB10 CS_2_Pin */
  GPIO_InitStruct.Pin = GPIO_PIN_10|CS_2_Pin;
  GPIO_InitStruct.Mode = GPIO_MODE_OUTPUT_PP;
  GPIO_InitStruct.Pull = GPIO_NOPULL;
  GPIO_InitStruct.Speed = GPIO_SPEED_FREQ_VERY_HIGH;
  HAL_GPIO_Init(GPIOB, &GPIO_InitStruct);

  /*Configure GPIO pins : START_2_Pin RESET_2_Pin */
  GPIO_InitStruct.Pin = START_2_Pin|RESET_2_Pin;
  GPIO_InitStruct.Mode = GPIO_MODE_OUTPUT_PP;
  GPIO_InitStruct.Pull = GPIO_NOPULL;
  GPIO_InitStruct.Speed = GPIO_SPEED_FREQ_VERY_HIGH;
  HAL_GPIO_Init(GPIOG, &GPIO_InitStruct);

  /*Configure GPIO pin : DRDY_2_Pin */
  GPIO_InitStruct.Pin = DRDY_2_Pin;
  GPIO_InitStruct.Mode = GPIO_MODE_IT_FALLING;
  GPIO_InitStruct.Pull = GPIO_NOPULL;
  HAL_GPIO_Init(DRDY_2_GPIO_Port, &GPIO_InitStruct);

  /*Configure GPIO pins : START_3_Pin RESET_3_Pin */
  GPIO_InitStruct.Pin = START_3_Pin|RESET_3_Pin;
  GPIO_InitStruct.Mode = GPIO_MODE_OUTPUT_PP;
  GPIO_InitStruct.Pull = GPIO_NOPULL;
  GPIO_InitStruct.Speed = GPIO_SPEED_FREQ_VERY_HIGH;
  HAL_GPIO_Init(GPIOA, &GPIO_InitStruct);

  /*Configure GPIO pin : DRDY_3_Pin */
  GPIO_InitStruct.Pin = DRDY_3_Pin;
  GPIO_InitStruct.Mode = GPIO_MODE_IT_FALLING;
  GPIO_InitStruct.Pull = GPIO_NOPULL;
  HAL_GPIO_Init(DRDY_3_GPIO_Port, &GPIO_InitStruct);

  /*Configure GPIO pins : GPI_1_Pin GPI_2_Pin */
  GPIO_InitStruct.Pin = GPI_1_Pin|GPI_2_Pin;
  GPIO_InitStruct.Mode = GPIO_MODE_INPUT;
  GPIO_InitStruct.Pull = GPIO_NOPULL;
  HAL_GPIO_Init(GPIOD, &GPIO_InitStruct);

  /*Configure GPIO pin : CS_3_Pin */
  GPIO_InitStruct.Pin = CS_3_Pin;
  GPIO_InitStruct.Mode = GPIO_MODE_OUTPUT_PP;
  GPIO_InitStruct.Pull = GPIO_NOPULL;
  GPIO_InitStruct.Speed = GPIO_SPEED_FREQ_VERY_HIGH;
  HAL_GPIO_Init(CS_3_GPIO_Port, &GPIO_InitStruct);

  /* EXTI interrupt init*/
  HAL_NVIC_SetPriority(EXTI1_IRQn, 0, 0);
  HAL_NVIC_EnableIRQ(EXTI1_IRQn);

  HAL_NVIC_SetPriority(EXTI7_IRQn, 0, 0);
  HAL_NVIC_EnableIRQ(EXTI7_IRQn);

  HAL_NVIC_SetPriority(EXTI11_IRQn, 0, 0);
  HAL_NVIC_EnableIRQ(EXTI11_IRQn);

}

/* USER CODE BEGIN 4 */

void UART_InitAllHandlers(void) {
	// Start receiving data on all four UARTs
	HAL_UART_Receive_IT(&huart4, uart1_rx_buffer, sizeof(uart1_rx_buffer));
	HAL_UART_Receive_IT(&huart8, uart2_rx_buffer, sizeof(uart2_rx_buffer));
	HAL_UART_Receive_IT(&huart5, uart5_rx_buffer, sizeof(uart5_rx_buffer));
	HAL_UART_Receive_IT(&huart10, uart4_rx_buffer, sizeof(uart4_rx_buffer));
}

void HAL_UART_RxCpltCallback(UART_HandleTypeDef *huart) {
	if (huart->Instance == UART4) {
		// Handle data received from UART1
		// Restart reception

		HAL_UART_Receive_IT(&huart4, &rcv,1);

		if(rcv == 'S' )
		{
			time_str_length=0;
			time_str[time_str_length++] = rcv;
			time_rcv =1;
		}
		else if(time_rcv==1)
		{
			time_str[time_str_length++] = rcv;
			if(time_str_length > 22)
			{
				time_str_length = 0 ;
				time_rcv = 0 ;
			}
		}
		if(rcv == 'E' )
		{
			if(time_str_length == 21)
			{
				//time_str[time_str_length++] = rcv;
				time_set = 1;
			}
			else
			{
				time_rcv = 0 ;
				time_str_length = 0 ;
				memset(time_str,0,sizeof(time_str));
			}
		}

		if(rcv == 'T')
		{
			command_str[command_str_index++] = rcv ;
			command_rcv  =1 ;

		}
		else if(command_rcv==1)
		{
			command_str[command_str_index++] = rcv ;
			if(command_str_index > 10)
			{
				command_str_index = 0 ;
				command_rcv = 0 ;
			}
		}
		if(command_rcv == 1 && rcv == 'E')
		{
			if(command_str_index == 4)
			{
				ATP_test  = 1;
				command_str_index = 0 ;
				command_rcv = 0 ;
			}
			else
			{
				command_str_index = 0 ;
				command_rcv = 0 ;
				memset(command_str,0,sizeof(command_str));
			}
		}

	}

	else if (huart->Instance == UART5) {

		// Handle data received from UART3
		//HAL_UART_Receive_IT(&huart5, &rcv, 1);

		//		if(rcv == 'S' )
		//		{
		//			time_str_length=0;
		//			time_str[time_str_length++] = rcv;
		//			time_rcv =1;
		//		}
		//		else if(time_rcv==1)
		//		{
		//			time_str[time_str_length++] = rcv;
		//			if(time_str_length > 22)
		//			{
		//				time_str_length = 0 ;
		//				time_rcv = 0 ;
		//			}
		//		}
		//		if(rcv == 'E' )
		//		{
		//			if(time_str_length == 21)
		//			{
		//				//time_str[time_str_length++] = rcv;
		//				time_set = 1;
		//			}
		//			else
		//			{
		//				time_rcv = 0 ;
		//				time_str_length = 0 ;
		//				memset(time_str,0,sizeof(time_str));
		//			}
		//		}
		//
		//		if(rcv == 'T')
		//		{
		//			command_str[command_str_index++] = rcv ;
		//			command_rcv  =1 ;
		//
		//		}
		//		else if(command_rcv==1)
		//		{
		//			command_str[command_str_index++] = rcv ;
		//			if(command_str_index > 10)
		//			{
		//				command_str_index = 0 ;
		//				command_rcv = 0 ;
		//			}
		//		}
		//		if(command_rcv == 1 && rcv == 'E')
		//		{
		//			if(command_str_index == 4)
		//			{
		//				ATP_test  = 1;
		//				command_str_index = 0 ;
		//				command_rcv = 0 ;
		//			}
		//			else
		//			{
		//				command_str_index = 0 ;
		//				command_rcv = 0 ;
		//				memset(command_str,0,sizeof(command_str));
		//			}
		//		}

		HAL_UART_Receive_IT(&huart5, &uart5_rx_buffer, sizeof(uart5_rx_buffer));

		if(uart5_rx_buffer == 'N')
		{
			NAND_Buf[NAND_index++] = uart5_rx_buffer ;
			NAND_flag  =1 ;

		}
		else if(NAND_flag==1)
		{
			NAND_Buf[NAND_index++] = uart5_rx_buffer ;
			if(NAND_index > 15)
			{
				NAND_index = 0 ;
				NAND_flag = 0 ;
			}
		}
		if(NAND_flag == 1 && uart5_rx_buffer == 'E')
		{

			NAND_flag = 0 ;
			NAND_index = 0 ;
//			memset(command_str,0,sizeof(command_str));

		}

	}
	else if (huart->Instance == UART8) {
		// Handle data received from UART2
		HAL_UART_Receive_IT(&huart8, uart2_rx_buffer, sizeof(uart2_rx_buffer));
	}
	else if (huart->Instance == USART10) {
		// Handle data received from UART4

		HAL_UART_Receive_IT(&huart10, uart4_rx_buffer, sizeof(uart4_rx_buffer));
	}
}

// User-defined callback to handle the data-ready event
void HAL_GPIO_EXTI_Falling_Callback(uint16_t GPIO_Pin)
{
	if (GPIO_Pin == DRDY_1_Pin)  // Check if the interrupt was caused by pin 0
	{

		//HAL_UART_Transmit_IT(&huart8, "DR_1\n\r", strlen("DR_1\n\r"));
		//HAL_Delay(1000);
		// Data ready logic
		// For example, read data from a sensor using SPI/I2C
	}
	else if (GPIO_Pin == DRDY_2_Pin)  // Check if the interrupt was caused by pin 0
	{
		//HAL_UART_Transmit_IT(&huart8, "DR_2\n\r", strlen("DR_1\n\r"));
		//HAL_Delay(1);
		// Data ready logic
		// For example, read data from a sensor using SPI/I2C
	}
	else if (GPIO_Pin == DRDY_3_Pin)  // Check if the interrupt was caused by pin 0
	{

		//HAL_UART_Transmit_IT(&huart8, "DR_3\n\r", strlen("DR_1\n\r"));
		//HAL_Delay(1);
		// Data ready logic
		// For example, read data from a sensor using SPI/I2C
	}
}
/* USER CODE END 4 */

void Error_Handler(void)
{
	__disable_irq();
	while (1)
	{
	}
}
